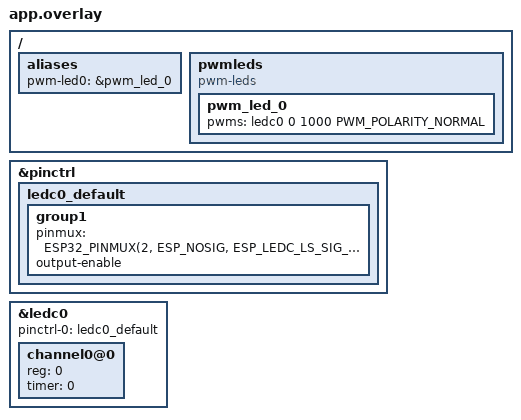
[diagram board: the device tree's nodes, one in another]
#include <zephyr/dt-bindings/pinctrl/esp32-pinctrl.h>

/ {
    aliases {
        pwm-led0 = &pwm_led_0;
    };

    pwmleds {
        compatible = "pwm-leds";
        pwm_led_0: pwm_led_0 {
            pwms = <&ledc0 0 1000 PWM_POLARITY_NORMAL>;
        };
    };
};

&pinctrl {
    ledc0_default: ledc0_default {
        group1 {
            pinmux = <ESP32_PINMUX(2, ESP_NOSIG, ESP_LEDC_LS_SIG_OUT0)>;
            output-enable;
        };
    };
};

&ledc0 {
    pinctrl-0 = <&ledc0_default>;
    pinctrl-names = "default";
    status = "okay";
    #address-cells = <1>;
    #size-cells = <0>;
    channel0@0 {
        reg = <0>;
        timer = <0>;
    };
};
